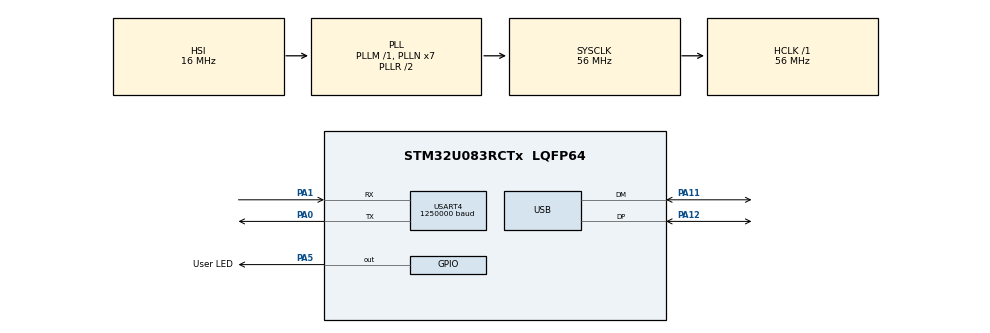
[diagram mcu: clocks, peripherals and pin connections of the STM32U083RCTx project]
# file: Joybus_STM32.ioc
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Dma.Request0=USART4_RX
Dma.USART4_RX.0.Direction=DMA_PERIPH_TO_MEMORY
Dma.USART4_RX.0.EventEnable=DISABLE
Dma.USART4_RX.0.Instance=DMA1_Channel1
Dma.USART4_RX.0.MemDataAlignment=DMA_MDATAALIGN_BYTE
Dma.USART4_RX.0.MemInc=DMA_MINC_ENABLE
Dma.USART4_RX.0.Mode=DMA_CIRCULAR
Dma.USART4_RX.0.PeriphDataAlignment=DMA_PDATAALIGN_BYTE
Dma.USART4_RX.0.PeriphInc=DMA_PINC_DISABLE
Dma.USART4_RX.0.Polarity=HAL_DMAMUX_REQ_GEN_RISING
Dma.USART4_RX.0.Priority=DMA_PRIORITY_LOW
Dma.USART4_RX.0.RequestNumber=1
Dma.USART4_RX.0.SignalID=NONE
Dma.USART4_RX.0.SyncEnable=DISABLE
Dma.USART4_RX.0.SyncPolarity=HAL_DMAMUX_SYNC_NO_EVENT
Dma.USART4_RX.0.SyncRequestNumber=1
Dma.USART4_RX.0.SyncSignalID=NONE
Mcu.Family=STM32U0
Mcu.Name=STM32U083RCTx
Mcu.Package=LQFP64
NVIC.DMA1_Channel1_IRQn=true\:0\:0\:false\:false\:true\:false\:true\:true
NVIC.PriorityGroup=NVIC_PRIORITYGROUP_2
NVIC.USB_DRD_FS_IRQn=true\:0\:0\:false\:false\:true\:true\:true\:true
PA0.Mode=Asynchronous
PA0.Signal=USART4_TX
PA1.Mode=Asynchronous
PA1.Signal=USART4_RX
PA11\ [PA9].Mode=Device
PA11\ [PA9].Signal=USB_DM
PA12\ [PA10].Mode=Device
PA12\ [PA10].Signal=USB_DP
PA13\ (SWDIO).GPIO_Label=SWDIO
PA13\ (SWDIO).Signal=DEBUG_JTMS-SWDIO
PA14\ (SWCLK).GPIO_Label=SWCLK
PA14\ (SWCLK).Signal=DEBUG_JTCK-SWCLK
PA5.GPIO_Label=User LED
PA5.Signal=GPIO_Output
ProjectManager.HeapSize=0x200
ProjectManager.StackSize=0x400
ProjectManager.TargetToolchain=CMake
RCC.ADCFreq_Value=56000000
RCC.AHBFreq_Value=56000000
RCC.CortexFreq_Value=56000000
RCC.HCLKFreq_Value=56000000
RCC.HSE_VALUE=4000000
RCC.HSI48_VALUE=48000000
RCC.HSI_VALUE=16000000
RCC.LSE_VALUE=32768
RCC.MSIClockRangeVal=RCC_MSIRANGE_11
RCC.MSI_VALUE=48000000
RCC.PLLN=7
RCC.SYSCLKFreq_VALUE=56000000
RCC.SYSCLKSource=RCC_SYSCLKSOURCE_PLLCLK
RCC.USBFreq_Value=48000000
RCC.VCOOutputFreq_Value=112000000
USART4.BaudRate=1250000
USART4.VirtualMode-Asynchronous=VM_ASYNC
USB.VirtualMode=Device_Only
VP_PWR_VS_SECSignals.Mode=Security/Privilege
board=NUCLEO-U083RC

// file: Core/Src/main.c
/* USER CODE BEGIN Header */
/**
  ******************************************************************************
  * @file           : main.c
  * @brief          : Main program body
  ******************************************************************************
  * @attention
  *
  * Copyright (c) 2025 STMicroelectronics.
  * All rights reserved.
  *
  * This software is licensed under terms that can be found in the LICENSE file
  * in the root directory of this software component.
  * If no LICENSE file comes with this software, it is provided AS-IS.
  *
  ******************************************************************************
  */
/* USER CODE END Header */
#include "main.h"

/* USER CODE BEGIN Includes */
#include "main.hpp"
/* USER CODE END Includes */

UART_HandleTypeDef huart4;
DMA_HandleTypeDef hdma_usart4_rx;

PCD_HandleTypeDef hpcd_USB_DRD_FS;

void SystemClock_Config(void);
static void MX_GPIO_Init(void);
static void MX_DMA_Init(void);
static void MX_USART4_UART_Init(void);
static void MX_USB_PCD_Init(void);

int main(void)
{

  /* MCU Configuration--------------------------------------------------------*/

  /* Reset of all peripherals, Initializes the Flash interface and the Systick. */
  HAL_Init();

  /* Configure the system clock */
  SystemClock_Config();

  /* Initialize all configured peripherals */
  MX_GPIO_Init();
  MX_DMA_Init();
  MX_USART4_UART_Init();
  MX_USB_PCD_Init();
  /* USER CODE BEGIN 2 */
  setup(&huart4);
  /* USER CODE END 2 */

  /* Infinite loop */
  /* USER CODE BEGIN WHILE */
  while (1)
  {
    loop();
    /* USER CODE END WHILE */

  }
}

void SystemClock_Config(void)
{
  RCC_OscInitTypeDef RCC_OscInitStruct = {0};
  RCC_ClkInitTypeDef RCC_ClkInitStruct = {0};

  /** Configure the main internal regulator output voltage
  */
  HAL_PWREx_ControlVoltageScaling(PWR_REGULATOR_VOLTAGE_SCALE1);

  /** Initializes the RCC Oscillators according to the specified parameters
  * in the RCC_OscInitTypeDef structure.
  */
  RCC_OscInitStruct.OscillatorType = RCC_OSCILLATORTYPE_HSI|RCC_OSCILLATORTYPE_MSI;
  RCC_OscInitStruct.HSIState = RCC_HSI_ON;
  RCC_OscInitStruct.HSICalibrationValue = RCC_HSICALIBRATION_DEFAULT;
  RCC_OscInitStruct.MSIState = RCC_MSI_ON;
  RCC_OscInitStruct.MSICalibrationValue = RCC_MSICALIBRATION_DEFAULT;
  RCC_OscInitStruct.MSIClockRange = RCC_MSIRANGE_11;
  RCC_OscInitStruct.PLL.PLLState = RCC_PLL_ON;
  RCC_OscInitStruct.PLL.PLLSource = RCC_PLLSOURCE_HSI;
  RCC_OscInitStruct.PLL.PLLM = RCC_PLLM_DIV1;
  RCC_OscInitStruct.PLL.PLLN = 7;
  RCC_OscInitStruct.PLL.PLLP = RCC_PLLP_DIV2;
  RCC_OscInitStruct.PLL.PLLQ = RCC_PLLQ_DIV2;
  RCC_OscInitStruct.PLL.PLLR = RCC_PLLR_DIV2;
  if (HAL_RCC_OscConfig(&RCC_OscInitStruct) != HAL_OK)
  {
    Error_Handler();
  }

  /** Initializes the CPU, AHB and APB buses clocks
  */
  RCC_ClkInitStruct.ClockType = RCC_CLOCKTYPE_HCLK|RCC_CLOCKTYPE_SYSCLK
                              |RCC_CLOCKTYPE_PCLK1;
  RCC_ClkInitStruct.SYSCLKSource = RCC_SYSCLKSOURCE_PLLCLK;
  RCC_ClkInitStruct.AHBCLKDivider = RCC_SYSCLK_DIV1;
  RCC_ClkInitStruct.APB1CLKDivider = RCC_HCLK_DIV1;

  if (HAL_RCC_ClockConfig(&RCC_ClkInitStruct, FLASH_LATENCY_2) != HAL_OK)
  {
    Error_Handler();
  }
}

static void MX_USART4_UART_Init(void)
{

  huart4.Instance = USART4;
  huart4.Init.BaudRate = 1250000;
  huart4.Init.WordLength = UART_WORDLENGTH_8B;
  huart4.Init.StopBits = UART_STOPBITS_1;
  huart4.Init.Parity = UART_PARITY_NONE;
  huart4.Init.Mode = UART_MODE_TX_RX;
  huart4.Init.HwFlowCtl = UART_HWCONTROL_NONE;
  huart4.Init.OverSampling = UART_OVERSAMPLING_16;
  huart4.Init.OneBitSampling = UART_ONE_BIT_SAMPLE_DISABLE;
  huart4.Init.ClockPrescaler = UART_PRESCALER_DIV1;
  huart4.AdvancedInit.AdvFeatureInit = UART_ADVFEATURE_NO_INIT;
  if (HAL_UART_Init(&huart4) != HAL_OK)
  {
    Error_Handler();
  }
  if (HAL_UARTEx_SetTxFifoThreshold(&huart4, UART_TXFIFO_THRESHOLD_1_8) != HAL_OK)
  {
    Error_Handler();
  }
  if (HAL_UARTEx_SetRxFifoThreshold(&huart4, UART_RXFIFO_THRESHOLD_1_8) != HAL_OK)
  {
    Error_Handler();
  }
  if (HAL_UARTEx_DisableFifoMode(&huart4) != HAL_OK)
  {
    Error_Handler();
  }

}

static void MX_USB_PCD_Init(void)
{

  hpcd_USB_DRD_FS.Instance = USB_DRD_FS;
  hpcd_USB_DRD_FS.Init.dev_endpoints = 8;
  hpcd_USB_DRD_FS.Init.speed = USBD_FS_SPEED;
  hpcd_USB_DRD_FS.Init.phy_itface = PCD_PHY_EMBEDDED;
  hpcd_USB_DRD_FS.Init.Sof_enable = DISABLE;
  hpcd_USB_DRD_FS.Init.low_power_enable = DISABLE;
  hpcd_USB_DRD_FS.Init.lpm_enable = DISABLE;
  hpcd_USB_DRD_FS.Init.battery_charging_enable = DISABLE;
  if (HAL_PCD_Init(&hpcd_USB_DRD_FS) != HAL_OK)
  {
    Error_Handler();
  }

}

static void MX_DMA_Init(void)
{

  /* DMA controller clock enable */
  __HAL_RCC_DMA1_CLK_ENABLE();

  /* DMA interrupt init */
  /* DMA1_Channel1_IRQn interrupt configuration */
  HAL_NVIC_SetPriority(DMA1_Channel1_IRQn, 0, 0);
  HAL_NVIC_EnableIRQ(DMA1_Channel1_IRQn);

}

static void MX_GPIO_Init(void)
{
  GPIO_InitTypeDef GPIO_InitStruct = {0};

  /* GPIO Ports Clock Enable */
  __HAL_RCC_GPIOA_CLK_ENABLE();

  /*Configure GPIO pin Output Level */
  HAL_GPIO_WritePin(User_LED_GPIO_Port, User_LED_Pin, GPIO_PIN_RESET);

  /*Configure GPIO pin : User_LED_Pin */
  GPIO_InitStruct.Pin = User_LED_Pin;
  GPIO_InitStruct.Mode = GPIO_MODE_OUTPUT_PP;
  GPIO_InitStruct.Pull = GPIO_NOPULL;
  GPIO_InitStruct.Speed = GPIO_SPEED_FREQ_LOW;
  HAL_GPIO_Init(User_LED_GPIO_Port, &GPIO_InitStruct);

}

void Error_Handler(void)
{
  __disable_irq();
  while (1)
  {
  }
}
